# MIMXRT685S_cm33 register map
Vendor: nxp.com; File version: 1.0
CPU: CM33 r2p0, little endian, MPU, FPU, VTOR, 3 interrupt priority bits
Registers are 32-bit, read-write, reset 0x0 unless marked. A register's access mark holds for its fields unless they carry their own. Offsets are from the block's base; [hi:lo] are bit positions; 'fields as' and 'values as' point back to an identical list; <NAME> marks a mode.

## USBPHY — Universal System Bus Physical Layer
Base 0x4013B000
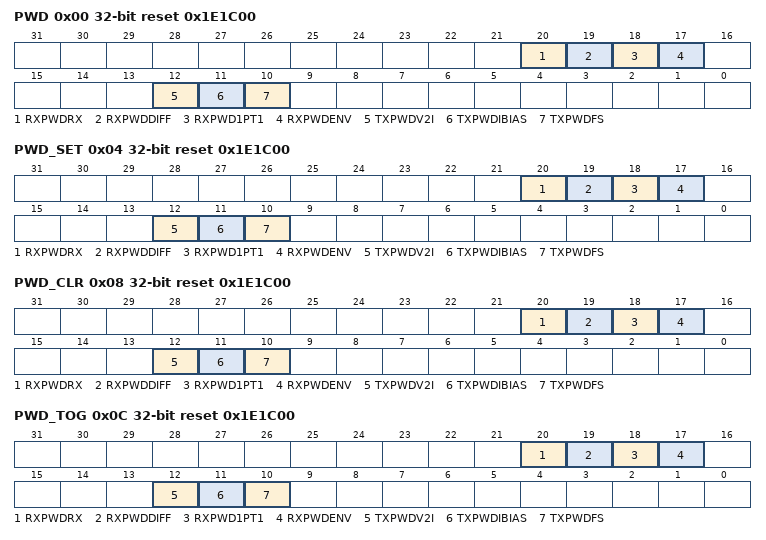
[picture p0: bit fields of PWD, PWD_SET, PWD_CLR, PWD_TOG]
0x00 PWD reset 0x1E1C00 — USB PHY Power-Down Register
  [20] RXPWDRX — This bit will be auto cleared if there is USB wakeup event while ENAUTOCLR_PHY_PWD bit of CTRL is enabled
    0=Normal operation; 1=Power-down the entire USB PHY receiver block except for the full-speed differential receiver
  [19] RXPWDDIFF — Note that this bit will be auto cleared if there is USB wakeup event while ENAUTOCLR_PHY_PWD bit of CTRL is enabled
    0=Normal operation; 1=Power-down the USB high-speed differential receive
  [18] RXPWD1PT1 — Note that this bit will be auto cleared if there is USB wakeup event while ENAUTOCLR_PHY_PWD bit of CTRL is enabled
    0=Normal operation; 1=Power-down the USB full-speed differential receiver
  [17] RXPWDENV — Note that this bit will be auto cleared if there is USB wakeup event while ENAUTOCLR_PHY_PWD bit of CTRL is enabled
    0=Normal operation; 1=Power-down the USB high-speed receiver envelope detector (squelch signal)
  [12] TXPWDV2I — Note that this bit will be auto cleared if there is USB wakeup event while ENAUTOCLR_PHY_PWD bit of CTRL is enabled
    0=Normal operation; 1=Power-down the USB PHY transmit V-to-I converter and the current mirror
  [11] TXPWDIBIAS — Note that this bit will be auto cleared if there is USB wakeup event while ENAUTOCLR_PHY_PWD bit of CTRL is enabled
    0=Normal operation; 1=Power-down the USB PHY current bias block for the transmitter. This bit should be set only when the
  [10] TXPWDFS — Note that this bit will be auto cleared if there is USB wakeup event while ENAUTOCLR_PHY_PWD bit of CTRL is enabled
    0=Normal operation; 1=Power-down the USB full-speed drivers. This turns off the current starvation sources and puts the
0x04 PWD_SET reset 0x1E1C00 — USB PHY Power-Down Register
  fields as PWD
0x08 PWD_CLR reset 0x1E1C00 — USB PHY Power-Down Register
  fields as PWD
0x0C PWD_TOG reset 0x1E1C00 — USB PHY Power-Down Register
  fields as PWD
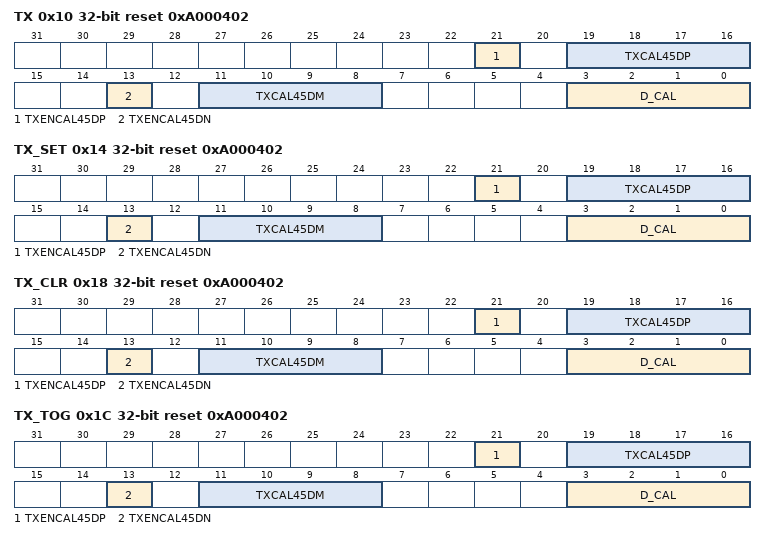
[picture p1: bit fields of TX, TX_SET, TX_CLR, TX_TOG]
0x10 TX reset 0xA000402 — USB PHY Transmitter Control Register
  [21] TXENCAL45DP — Enable resistance calibration on DP.
  [19:16] TXCAL45DP — Decode to trim the nominal 45ohm series termination resistance to the USB_DP output pin
  [13] TXENCAL45DN — Enable resistance calibration on DN.
  [11:8] TXCAL45DM — Decode to trim the nominal 45ohm series termination resistance to the USB_DM output pin
  [3:0] D_CAL — Decode to trim the nominal 17
    0=Maximum current, approximately 19% above nominal; 7=Nominal; 15=Minimum current, approximately 19% below nominal
0x14 TX_SET reset 0xA000402 — USB PHY Transmitter Control Register
  fields as TX
0x18 TX_CLR reset 0xA000402 — USB PHY Transmitter Control Register
  fields as TX
0x1C TX_TOG reset 0xA000402 — USB PHY Transmitter Control Register
  fields as TX
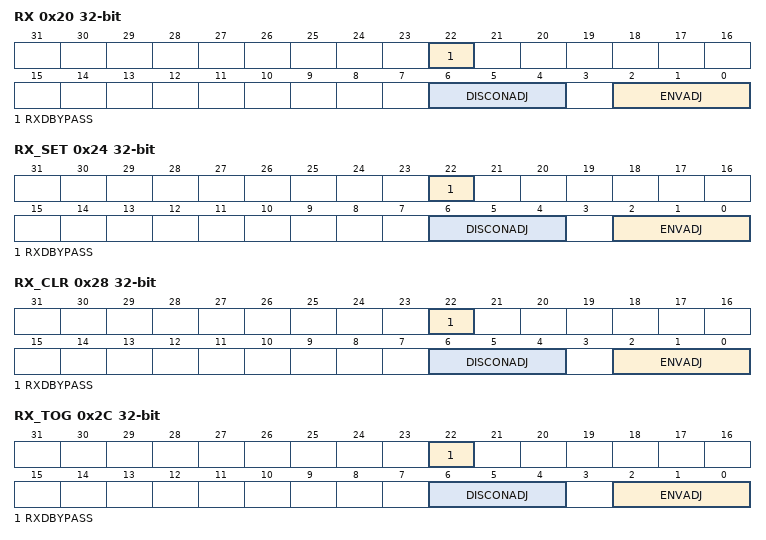
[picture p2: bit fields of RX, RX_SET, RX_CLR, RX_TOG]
0x20 RX — USB PHY Receiver Control Register
  [22] RXDBYPASS — This test mode is intended for lab use only, replace FS differential receiver with DP single ended receiver
    0=Normal operation; 1=Use the output of the USB_DP single-ended receiver in place of the full-speed differential receiver
  [6:4] DISCONADJ — The DISCONADJ field adjusts the trip point for the disconnect detector.
    0=Trip-Level Voltage is 0.56875 V; 1=Trip-Level Voltage is 0.55000 V; 2=Trip-Level Voltage is 0.58125 V; 3=Trip-Level Voltage is 0.60000 V
  [2:0] ENVADJ — The ENVADJ field adjusts the trip point for the envelope detector
    0=Trip-Level Voltage is 0.1000 V; 1=Trip-Level Voltage is 0.1125 V; 2=Trip-Level Voltage is 0.1250 V; 3=Trip-Level Voltage is 0.0875 V
0x24 RX_SET — USB PHY Receiver Control Register
  fields as RX
0x28 RX_CLR — USB PHY Receiver Control Register
  fields as RX
0x2C RX_TOG — USB PHY Receiver Control Register
  fields as RX
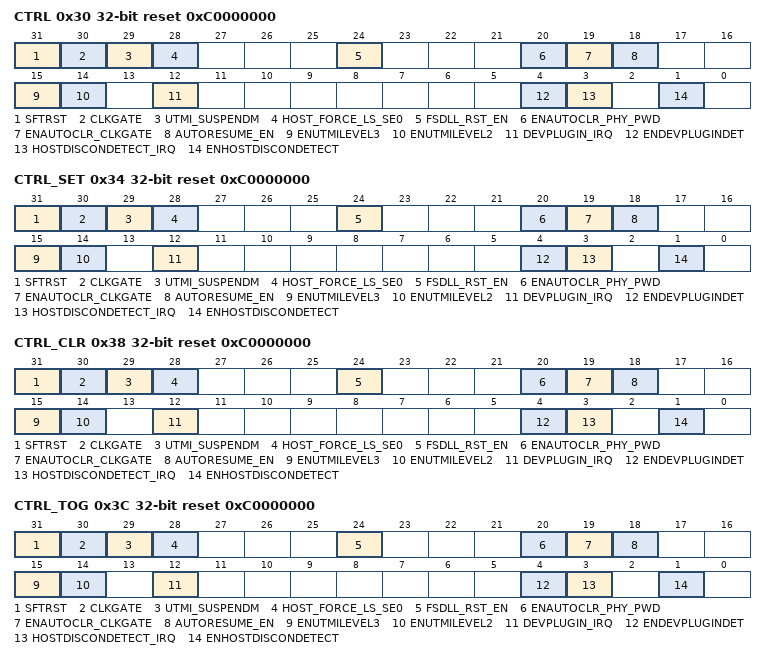
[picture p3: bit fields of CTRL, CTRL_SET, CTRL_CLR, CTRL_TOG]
0x30 CTRL reset 0xC0000000 — USB PHY General Control Register
  [31] SFTRST — Writing a 1 to this bit will soft-reset the PWD, TX, RX, and CTRL registers
  [30] CLKGATE — Gate UTMI Clocks
  [29] UTMI_SUSPENDM — Used by the PHY to indicate a powered-down state
  [28] HOST_FORCE_LS_SE0 — Forces the next FS packet that is transmitted to have a EOP with low-speed timing
  [24] FSDLL_RST_EN — Enables the feature to reset the FSDLL lock detection logic at the end of each TX packet.
  [20] ENAUTOCLR_PHY_PWD — Enables the feature to auto-clear the PWD register bits in PWD if there is wakeup event while USB is suspended
  [19] ENAUTOCLR_CLKGATE — Enables the feature to auto-clear the CLKGATE bit if there is wakeup event while USB is suspended
  [18] AUTORESUME_EN — Enable the auto resume feature, when set, HW will use 32KHz clock to send Resume to respond to the device remote wakeup(for host mode only)
  [15] ENUTMILEVEL3 — Enables UTMI+ Level 3 operation for the USB HS PHY
  [14] ENUTMILEVEL2 — Enables UTMI+ Level 2 operation for the USB HS PHY
  [12] DEVPLUGIN_IRQ — Indicates that the device is connected
  [4] ENDEVPLUGINDET — Enables non-standard resistive plugged-in detection This bit field controls connection of nominal 200kohm resistors to both the USB_DP and USB_DM pins as one method of detecting when a USB cable is attached in device mode
    0=Disables 200kohm pullup resistors on USB_DP and USB_DM pins (Default); 1=Enables 200kohm pullup resistors on USB_DP and USB_DM pins
  [3] HOSTDISCONDETECT_IRQ — Indicates that the device has disconnected in High-Speed mode
  [1] ENHOSTDISCONDETECT — For host mode, enables high-speed disconnect detector
0x34 CTRL_SET reset 0xC0000000 — USB PHY General Control Register
  fields as CTRL
0x38 CTRL_CLR reset 0xC0000000 — USB PHY General Control Register
  fields as CTRL
0x3C CTRL_TOG reset 0xC0000000 — USB PHY General Control Register
  fields as CTRL
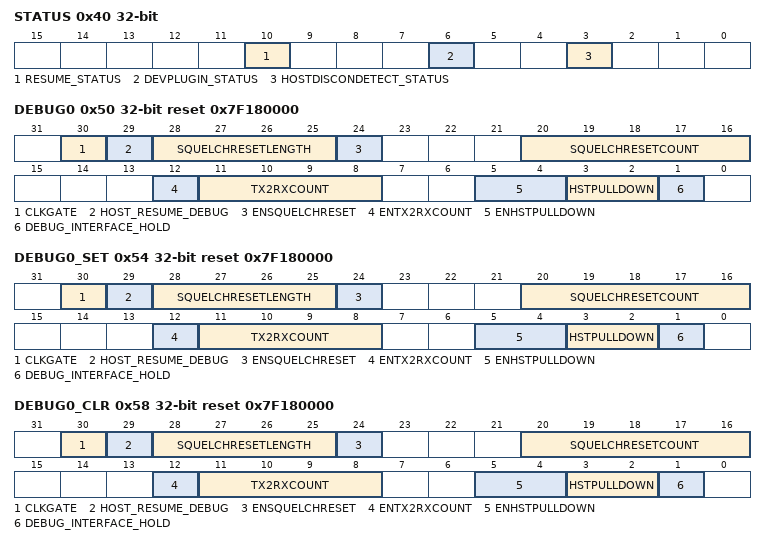
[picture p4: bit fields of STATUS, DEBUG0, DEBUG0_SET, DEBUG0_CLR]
0x40 STATUS — USB PHY Status Register
  [10] RESUME_STATUS — Indicates that the host is sending a wake-up after Suspend and has triggered an interrupt.
  [6] DEVPLUGIN_STATUS — Status indicator for non-standard resistive plugged-in detection Indicates that the device has been connected on the USB_DP and USB_DM lines using the nonstandard resistive plugged-in detection method controlled by CTRL[4]
    0=No attachment to a USB host is detected; 1=Cable attachment to a USB host is detected
  [3] HOSTDISCONDETECT_STATUS — Indicates at the local host (downstream) port that the remote device has disconnected while in High-Speed mode
    0=USB cable disconnect has not been detected at the local host; 1=USB cable disconnect has been detected at the local host
0x50 DEBUG0 reset 0x7F180000 — USB PHY Debug Register 0
  [30] CLKGATE — Gate Test Clocks
  [29] HOST_RESUME_DEBUG — Choose to trigger the host resume SE0 with HOST_FORCE_LS_SE0 = 0 or UTMI_SUSPEND = 1.
  [28:25] SQUELCHRESETLENGTH — Duration of RESET in terms of the number of 480-MHz cycles.
  [24] ENSQUELCHRESET — Set bit to allow squelch to reset high-speed receive.
  [20:16] SQUELCHRESETCOUNT — Delay in between the detection of squelch to the reset of high-speed RX.
  [12] ENTX2RXCOUNT — Set this bit to allow a countdown to transition in between TX and RX.
  [11:8] TX2RXCOUNT — Delay in between the end of transmit to the beginning of receive
  [5:4] ENHSTPULLDOWN — This bit field selects host pulldown overdrive mode
  [3:2] HSTPULLDOWN — This bit field selects whether to connect pulldown resistors on the USB_DP/USB_DM pins if the corresponding pulldown overdrive mode is enabled through DEBUG[5:4} Set bit 3 to value 1'b1 to connect the 15ohm pulldown on USB_DP line
  [1] DEBUG_INTERFACE_HOLD — Use holding registers to assist in timing for external UTMI interface.
0x54 DEBUG0_SET reset 0x7F180000 — USB PHY Debug Register 0
  fields as DEBUG0
0x58 DEBUG0_CLR reset 0x7F180000 — USB PHY Debug Register 0
  fields as DEBUG0
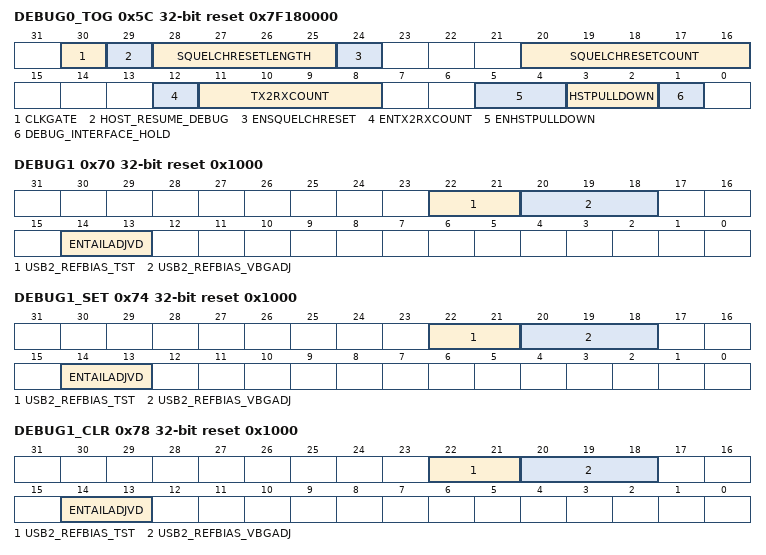
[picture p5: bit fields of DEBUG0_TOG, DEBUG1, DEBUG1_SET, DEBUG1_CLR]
0x5C DEBUG0_TOG reset 0x7F180000 — USB PHY Debug Register 0
  fields as DEBUG0
0x70 DEBUG1 reset 0x1000 — UTMI Debug Status Register 1
  [22:21] USB2_REFBIAS_TST — Bias current control for usb2_phy
  [20:18] USB2_REFBIAS_VBGADJ — Adjustment bits on bandgap
  [14:13] ENTAILADJVD — Delay increment of the rise of squelch:
    0=Delay is nominal; 1=Delay is +20%; 2=Delay is -20%; 3=Delay is -40%
0x74 DEBUG1_SET reset 0x1000 — UTMI Debug Status Register 1
  fields as DEBUG1
0x78 DEBUG1_CLR reset 0x1000 — UTMI Debug Status Register 1
  fields as DEBUG1
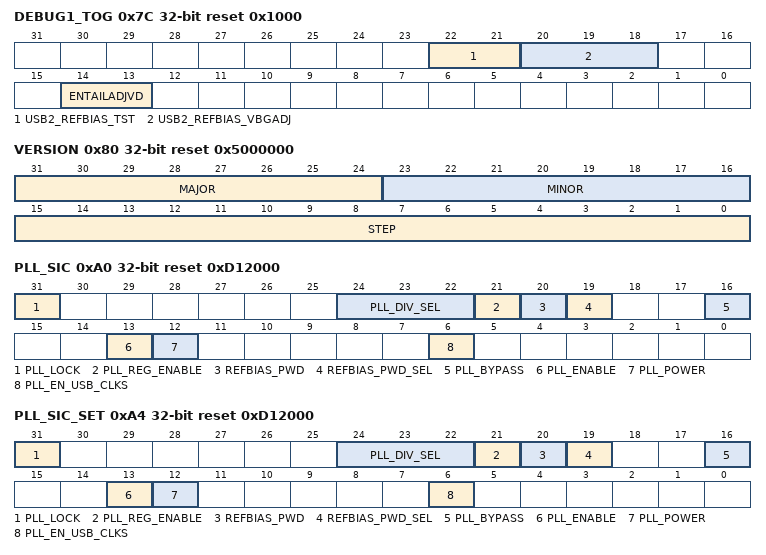
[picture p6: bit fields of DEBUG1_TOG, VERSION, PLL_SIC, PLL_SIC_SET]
0x7C DEBUG1_TOG reset 0x1000 — UTMI Debug Status Register 1
  fields as DEBUG1
0x80 VERSION ro reset 0x5000000 — UTMI RTL Version
  [31:24] MAJOR — Fixed read-only value reflecting the MAJOR field of the RTL versio
  [23:16] MINOR — Fixed read-only value reflecting the MINOR field of the RTL version
  [15:0] STEP — Fixed read-only value reflecting the stepping of the RTL version.
0xA0 PLL_SIC reset 0xD12000 — USB PHY PLL Control/Status Register
  [31] PLL_LOCK — USB PLL lock status indicator
    0=PLL is not currently locked; 1=PLL is currently locked
  [24:22] PLL_DIV_SEL — This field controls the USB PLL feedback loop divider
    0=Divide by 13; 1=Divide by 15; 2=Divide by 16; 3=Divide by 20; 4=Divide by 22; 5=Divide by 25; 6=Divide by 30; 7=Divide by 240
  [21] PLL_REG_ENABLE — This field controls the USB PLL regulator, set to enable the regulator
  [20] REFBIAS_PWD — Power down the reference bias This bit is only used when REFBIAS_PWD_SEL is set to 1.
  [19] REFBIAS_PWD_SEL — Reference bias power down select.
    0=Selects PLL_POWER to control the reference bias; 1=Selects REFBIAS_PWD to control the reference bias
  [16] PLL_BYPASS — Bypass the USB PLL.
  [13] PLL_ENABLE — Enables the clock output from the USB PLL
  [12] PLL_POWER — Power up the USB PLL
  [6] PLL_EN_USB_CLKS — Enables the USB clock from PLL to USB PHY
0xA4 PLL_SIC_SET reset 0xD12000 — USB PHY PLL Control/Status Register
  fields as PLL_SIC
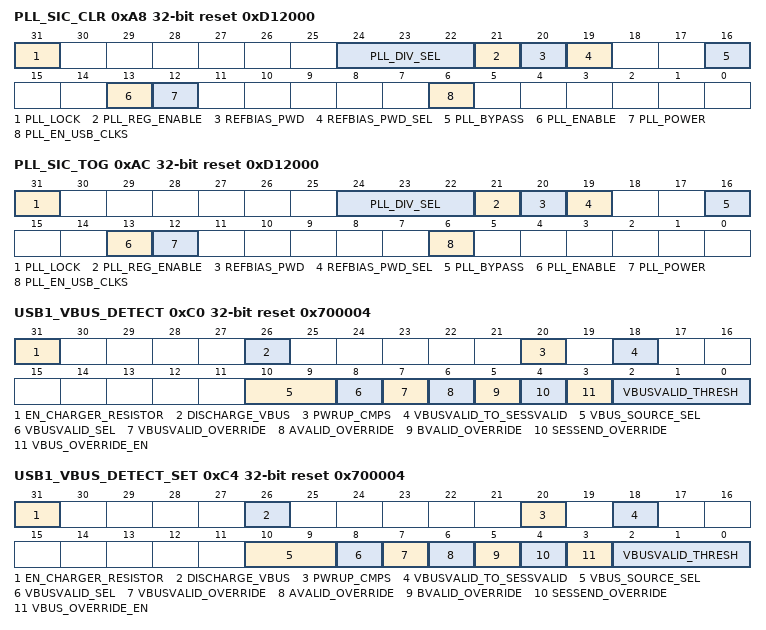
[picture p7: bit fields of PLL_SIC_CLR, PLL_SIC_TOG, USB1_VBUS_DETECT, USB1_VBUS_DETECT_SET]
0xA8 PLL_SIC_CLR reset 0xD12000 — USB PHY PLL Control/Status Register
  fields as PLL_SIC
0xAC PLL_SIC_TOG reset 0xD12000 — USB PHY PLL Control/Status Register
  fields as PLL_SIC
0xC0 USB1_VBUS_DETECT reset 0x700004 — USB PHY VBUS Detect Control Register
  [31] EN_CHARGER_RESISTOR — Enables resistors used for an older method of resistive battery charger detection
    0=Disable resistive charger detection resistors on USB_DP and USB_DP; 1=Enable resistive charger detection resistors on USB_DP and USB_DP
  [26] DISCHARGE_VBUS — Controls VBUS discharge resistor This bit field controls a nominal 22kohm resistor between the USB1_VBUS pin and ground
    0=VBUS discharge resistor is disabled (Default); 1=VBUS discharge resistor is enabled
  [20] PWRUP_CMPS — Enables the VBUS_VALID comparator Powers up the comparator used for the VBUS_VALID detector
    0=Powers down the VBUS_VALID comparator; 1=Enables the VBUS_VALID comparator (default)
  [18] VBUSVALID_TO_SESSVALID — Selects the comparator used for VBUS_VALID This bit field controls the comparator used to report the VBUS_VALID results in USB1_VBUS_DETECT[3] between the VBUS_VALID comparator and the Session Valid comparator
    0=Use the VBUS_VALID comparator for VBUS_VALID results; 1=Use the Session End comparator for VBUS_VALID results. The Session End threshold is >0.8V and <4.0V.
  [10:9] VBUS_SOURCE_SEL — Selects the source of the VBUS_VALID signal reported to the USB controller This is one of the bit fields that selects the source of the VBUS_VALID signal reported to the USB controller
    0=Use the VBUS_VALID comparator results for signal reported to the USB controller (Default); 1=Use the Session Valid comparator results for signal reported to the USB controller; 2=Use the Session Valid comparator results for signal reported to the USB controller
  [8] VBUSVALID_SEL — Selects the source of the VBUS_VALID signal reported to the USB controller This is one of the bit fields that selects the source of the VBUS_VALID signal reported to the USB controller
    0=Use the VBUS_VALID comparator results for signal reported to the USB controller (Default); 1=Use the VBUS_VALID_3V detector results for signal reported to the USB controller
  [7] VBUSVALID_OVERRIDE — Override value for VBUS_VALID signal sent to USB controller The bit field provides the value for VBUS_VALID reported to the USB controller if the value of USB1_VBUS_DETECT[3] is set to 1'b1
  [6] AVALID_OVERRIDE — Override value for A-Device Session Valid The bit field provides the value for USB1_VBUS_DET_STAT[2] if USB_VBUS_DETECT[3] is set to value 1'b1
  [5] BVALID_OVERRIDE — Override value for B-Device Session Valid The bit field provides the value for USB1_VBUS_DET_STAT[1] if USB_VBUS_DETECT[3] is set to value 1'b1
  [4] SESSEND_OVERRIDE — Override value for SESSEND The bit field provides the value for USB1_VBUS_DET_STAT[0] if USB_VBUS_DETECT[3] is set to value 1'b1
  [3] VBUS_OVERRIDE_EN — VBUS detect signal override enable
    0=Use the results of the internal VBUS_VALID and Session Valid comparators for VBUS_VALID, AVALID, BVALID, and SESSEND (Default); 1=Use the override values for VBUS_VALID, AVALID, BVALID, and SESSEND
  [2:0] VBUSVALID_THRESH — Sets the threshold for the VBUSVALID comparator
    0=4.0V; 1=4.1V; 2=4.2V; 3=4.3V; 4=4.4V(Default); 5=4.5V; 6=4.6V; 7=4.7V
0xC4 USB1_VBUS_DETECT_SET reset 0x700004 — USB PHY VBUS Detect Control Register
  fields as USB1_VBUS_DETECT
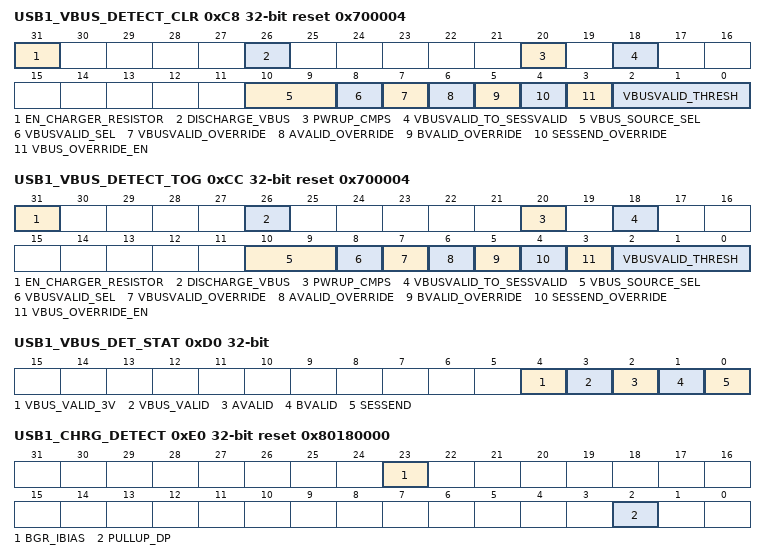
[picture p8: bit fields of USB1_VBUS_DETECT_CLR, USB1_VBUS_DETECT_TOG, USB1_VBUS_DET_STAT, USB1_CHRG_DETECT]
0xC8 USB1_VBUS_DETECT_CLR reset 0x700004 — USB PHY VBUS Detect Control Register
  fields as USB1_VBUS_DETECT
0xCC USB1_VBUS_DETECT_TOG reset 0x700004 — USB PHY VBUS Detect Control Register
  fields as USB1_VBUS_DETECT
0xD0 USB1_VBUS_DET_STAT ro — USB PHY VBUS Detector Status Register
  [4] VBUS_VALID_3V — VBUS_VALID_3V detector status The VBUS_VALID_3V detector has a lower threshold for the voltage on the USB1_VBUS pin than either the Session Valid or VBUS_VALID comparators
    0=VBUS voltage is below VBUS_VALID_3V threshold; 1=VBUS voltage is above VBUS_VALID_3V threshold
  [3] VBUS_VALID — VBUS voltage status This bit field shows the result of VBUS_VALID detection for the USB1_VBUS pin
    0=VBUS is below the comparator threshold; 1=VBUS is above the comparator threshold
  [2] AVALID — A-Device Session Valid status A-Device Session Valid status, determined by the Session Valid comparator
    0=The VBUS voltage is below the Session Valid threshold; 1=The VBUS voltage is above the Session Valid threshold
  [1] BVALID — B-Device Session Valid status B-Device Session Valid status, determined by the Session Valid comparator
    values as AVALID
  [0] SESSEND — Session End indicator Session End status, value inverted from Session Valid comparator
    0=The VBUS voltage is above the Session Valid threshold; 1=The VBUS voltage is below the Session Valid threshold
0xE0 USB1_CHRG_DETECT reset 0x80180000 — USB PHY Charger Detect Control Register
  [23] BGR_IBIAS — USB charge detector bias current reference This bit determines the reference for the bias current of the USB charge detector
    0=Bias current is derived from the USB PHY internal current generator; 1=Bias current is derived from the reference generator of the bandgap
  [2] PULLUP_DP — This bit is used to pull up DP, for digital charge detect.
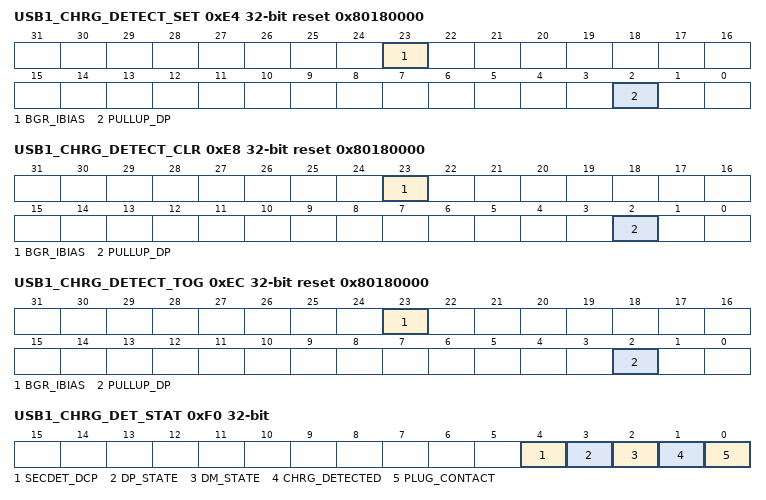
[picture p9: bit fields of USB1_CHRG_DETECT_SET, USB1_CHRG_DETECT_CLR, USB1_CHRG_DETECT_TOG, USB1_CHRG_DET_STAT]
0xE4 USB1_CHRG_DETECT_SET reset 0x80180000 — USB PHY Charger Detect Control Register
  fields as USB1_CHRG_DETECT
0xE8 USB1_CHRG_DETECT_CLR reset 0x80180000 — USB PHY Charger Detect Control Register
  fields as USB1_CHRG_DETECT
0xEC USB1_CHRG_DETECT_TOG reset 0x80180000 — USB PHY Charger Detect Control Register
  fields as USB1_CHRG_DETECT
0xF0 USB1_CHRG_DET_STAT ro — USB PHY Charger Detect Status Register
  [4] SECDET_DCP — Battery Charging Secondary Detection phase output During the USB Battery Charging Secondary Detection phase using the USBHSDCD module, this bit field indicates which kind of Charging Port was detected
    0=Charging Downstream Port (CDP) has been detected; 1=Downstream Charging Port (DCP) has been detected
  [3] DP_STATE — Single ended receiver output for the USB_DP pin, from charger detection circuits.
    0=USB_DP pin voltage is < 0.8V; 1=USB_DP pin voltage is > 2.0V
  [2] DM_STATE — Single ended receiver output for the USB_DM pin, from charger detection circuits.
    0=USB_DM pin voltage is < 0.8V; 1=USB_DM pin voltage is > 2.0V
  [1] CHRG_DETECTED — Battery Charging Primary Detection phase output During the USB Battery Charging Primary Detection phase using the USBHSDCD module, this bit field indicates whether a Standard Downstream Port or Charging Port was detected
    0=Standard Downstream Port (SDP) has been detected; 1=Charging Port has been detected
  [0] PLUG_CONTACT — Battery Charging Data Contact Detection phase output During the Data Contact Detection phase per the USB Battery Charging Specification Revision 1
    0=No USB cable attachment has been detected; 1=A USB cable attachment between the device and host has been detected
0x100 ANACTRL reset 0xA000402 — USB PHY Analog Control Register
  [10] DEV_PULLDOWN — Setting this field to 1'b1 will enable the 15kohm pulldown resistors on both USB_DP and USB_DM pins
    0=The 15kohm nominal pulldowns on the USB_DP and USB_DM pinsare disabled in device mode; 1=The 15kohm nominal pulldowns on the USB_DP and USB_DM pinsare enabled in device mode
0x104 ANACTRL_SET reset 0xA000402 — USB PHY Analog Control Register
  fields as ANACTRL
0x108 ANACTRL_CLR reset 0xA000402 — USB PHY Analog Control Register
  fields as ANACTRL
0x10C ANACTRL_TOG reset 0xA000402 — USB PHY Analog Control Register
  fields as ANACTRL
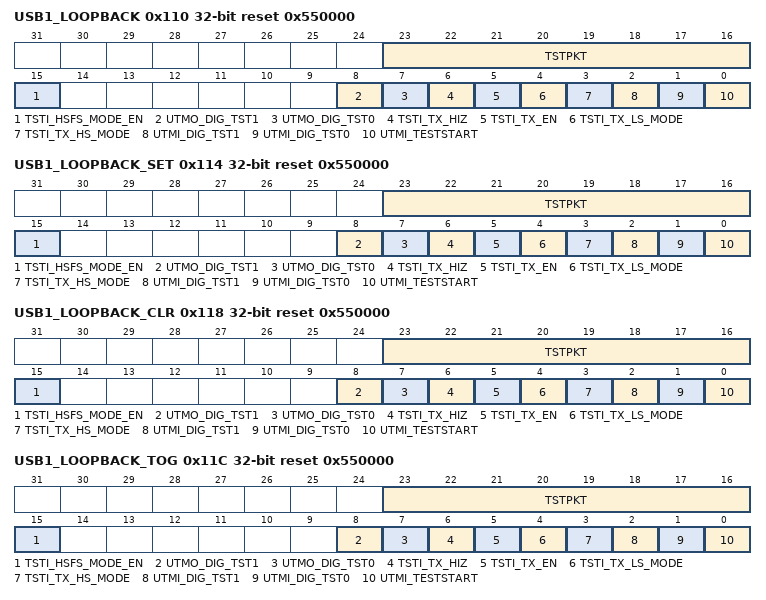
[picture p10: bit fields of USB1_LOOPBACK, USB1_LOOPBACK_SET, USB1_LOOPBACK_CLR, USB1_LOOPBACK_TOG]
0x110 USB1_LOOPBACK reset 0x550000 — USB PHY Loopback Control/Status Register
  [23:16] TSTPKT — Selects the packet data byte used for USB loopback testing in Pulse mode
  [15] TSTI_HSFS_MODE_EN — Setting this bit field to value 1'b1 will enable the loopback test to dynamically change the packet speed
  [8] UTMO_DIG_TST1 — This read-only bit is a status bit for USB loopback test
  [7] UTMO_DIG_TST0 — This read-only bit is a status bit for USB loopback test results
  [6] TSTI_TX_HIZ — Sets TX Hi-Z for USB loopback test.
  [5] TSTI_TX_EN — Enable TX for USB loopback test.
  [4] TSTI_TX_LS_MODE — Set to value 1'b1 to choose LS for USB loopback testing, set to value 1'b0 to choose HS or FS mode which is defined by TSTI1_TX_HS
  [3] TSTI_TX_HS_MODE — Select HS or FS mode for USB loopback testing
  [2] UTMI_DIG_TST1 — Mode control for USB loopback test
  [1] UTMI_DIG_TST0 — Mode control for USB loopback test
  [0] UTMI_TESTSTART — This bit enables the USB loopback test.
0x114 USB1_LOOPBACK_SET reset 0x550000 — USB PHY Loopback Control/Status Register
  fields as USB1_LOOPBACK
0x118 USB1_LOOPBACK_CLR reset 0x550000 — USB PHY Loopback Control/Status Register
  fields as USB1_LOOPBACK
0x11C USB1_LOOPBACK_TOG reset 0x550000 — USB PHY Loopback Control/Status Register
  fields as USB1_LOOPBACK
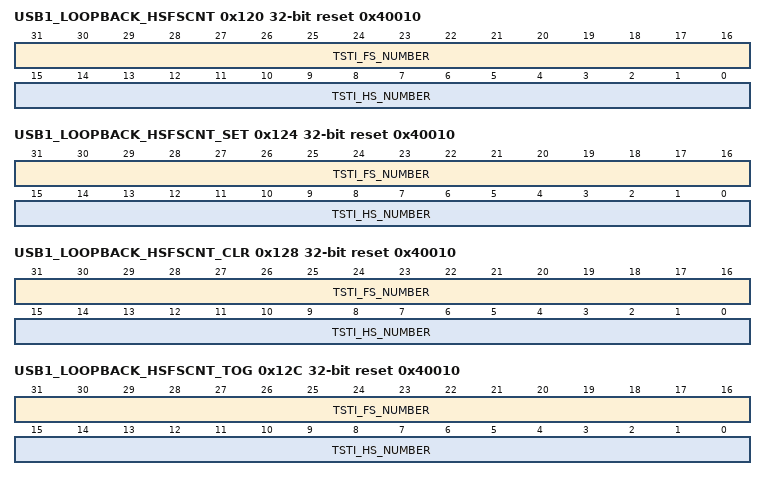
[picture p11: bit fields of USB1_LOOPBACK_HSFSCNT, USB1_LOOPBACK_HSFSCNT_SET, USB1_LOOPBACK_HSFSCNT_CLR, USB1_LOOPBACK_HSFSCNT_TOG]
0x120 USB1_LOOPBACK_HSFSCNT reset 0x40010 — USB PHY Loopback Packet Number Select Register
  [31:16] TSTI_FS_NUMBER — Full speed packet number, used when USB1_LOOPBACK[TSTI_HSFS_MODE_EN] is set to value 1'b1.
  [15:0] TSTI_HS_NUMBER — High speed packet number, used when USB1_LOOPBACK[TSTI_HSFS_MODE_EN] is set to value 1'b1.
0x124 USB1_LOOPBACK_HSFSCNT_SET reset 0x40010 — USB PHY Loopback Packet Number Select Register
  fields as USB1_LOOPBACK_HSFSCNT
0x128 USB1_LOOPBACK_HSFSCNT_CLR reset 0x40010 — USB PHY Loopback Packet Number Select Register
  fields as USB1_LOOPBACK_HSFSCNT
0x12C USB1_LOOPBACK_HSFSCNT_TOG reset 0x40010 — USB PHY Loopback Packet Number Select Register
  fields as USB1_LOOPBACK_HSFSCNT
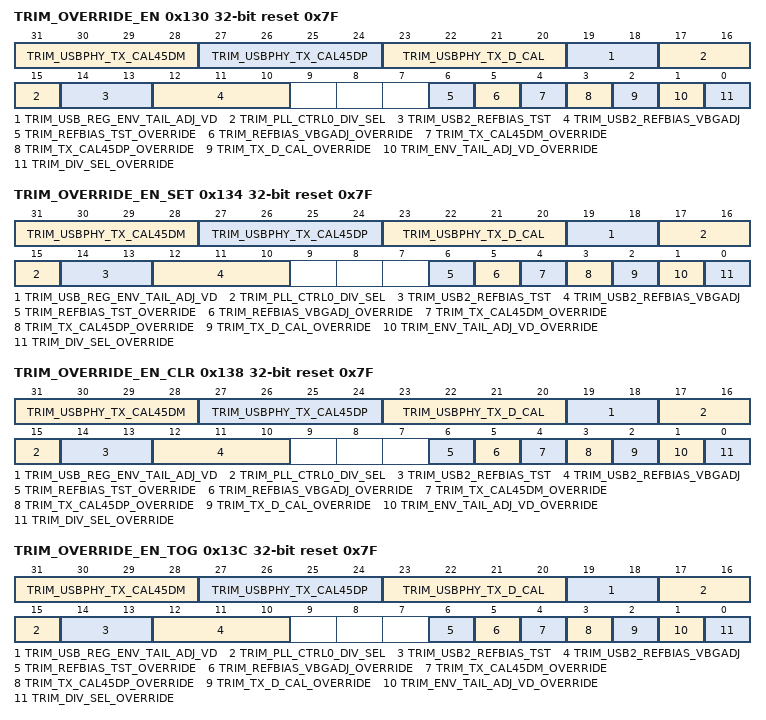
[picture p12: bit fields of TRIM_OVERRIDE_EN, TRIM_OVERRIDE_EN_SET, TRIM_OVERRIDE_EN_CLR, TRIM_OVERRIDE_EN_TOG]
0x130 TRIM_OVERRIDE_EN reset 0x7F — USB PHY Trim Override Enable Register
  [31:28] TRIM_USBPHY_TX_CAL45DM — IFR value of TX_CAL45DM.
  [27:24] TRIM_USBPHY_TX_CAL45DP — IFR value of TX_CAL45DP.
  [23:20] TRIM_USBPHY_TX_D_CAL — IFR value of TX_D_CAL.
  [19:18] TRIM_USB_REG_ENV_TAIL_ADJ_VD — IFR value of ENV_TAIL_ADJ.
  [17:15] TRIM_PLL_CTRL0_DIV_SEL — IFR value of PLL_DIV_SEL.
  [14:13] TRIM_USB2_REFBIAS_TST — Bias current control for usb2_phy
  [12:10] TRIM_USB2_REFBIAS_VBGADJ — Adjustment bits for bandgap
  [6] TRIM_REFBIAS_TST_OVERRIDE — Override enable for bias current control When this field is set, the register value in DEBUG1[22:21] will be used
  [5] TRIM_REFBIAS_VBGADJ_OVERRIDE — Override enable for bandgap adjustment
  [4] TRIM_TX_CAL45DM_OVERRIDE — Override enable for TX_CAL45DM, when set, the register value in TX[11:8] will be used.
  [3] TRIM_TX_CAL45DP_OVERRIDE — Override enable for TX_CAL45DP, when set, the register value in TX[19:16] will be used.
  [2] TRIM_TX_D_CAL_OVERRIDE — Override enable for TX_D_CAL, when set, the register value in TX[3:0] will be used.
  [1] TRIM_ENV_TAIL_ADJ_VD_OVERRIDE — Override enable for ENV_TAIL_ADJ, when set, the register value in DEBUG1[14:13] will be used.
  [0] TRIM_DIV_SEL_OVERRIDE — Override enable for PLL_DIV_SEL, when set, the register value in PLL_SIC[1:0] will be used.
0x134 TRIM_OVERRIDE_EN_SET reset 0x7F — USB PHY Trim Override Enable Register
  fields as TRIM_OVERRIDE_EN
0x138 TRIM_OVERRIDE_EN_CLR reset 0x7F — USB PHY Trim Override Enable Register
  fields as TRIM_OVERRIDE_EN
0x13C TRIM_OVERRIDE_EN_TOG reset 0x7F — USB PHY Trim Override Enable Register
  fields as TRIM_OVERRIDE_EN
